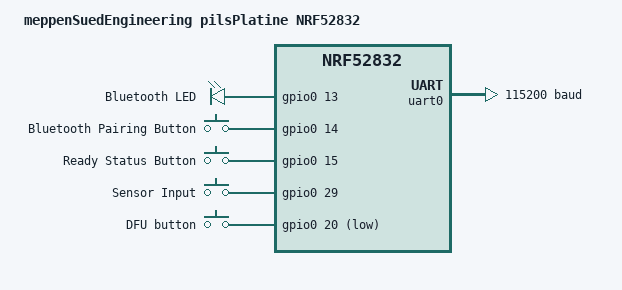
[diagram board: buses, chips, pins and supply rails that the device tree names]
/*
 * Copyright (c) 2017 Shawn Nock <shawn@monadnock.ca>
 * Copyright (c) 2017 Linaro Limited
 * Copyright (c) 2021 Michal Morsisko
 *
 * SPDX-License-Identifier: Apache-2.0
 */

/dts-v1/;
#include <nordic/nrf52832_qfaa.dtsi>
#include "pilsPlatine_nrf52832-pinctrl.dtsi"
#include <zephyr/dt-bindings/input/input-event-codes.h>

/ {
	model = "meppenSuedEngineering pilsPlatine NRF52832";
	compatible = "meppenSuedEngineering,pilsPlatine-nrf52832";

	chosen {
		zephyr,shell-uart = &uart0;
		zephyr,console = &uart0;
		zephyr,uart-mcumgr = &uart0;
		zephyr,bt-mon-uart = &uart0;
		zephyr,bt-c2h-uart = &uart0;
		zephyr,sram = &sram0;
		zephyr,flash = &flash0;
		zephyr,code-partition = &slot0_partition;
	};

	leds {
		compatible = "gpio-leds";
		led0: led_0 {
			gpios = <&gpio0 13 GPIO_ACTIVE_HIGH>;
			label = "Bluetooth LED";
		};
	};


	buttons {
		compatible = "gpio-keys";
		button0: button_0 {
			gpios = <&gpio0 14 (GPIO_PULL_UP | GPIO_ACTIVE_HIGH)>;
			label = "Bluetooth Pairing Button";
			zephyr,code = <INPUT_KEY_0>;
		};
		button1: button_1 {
			gpios = <&gpio0 15 (GPIO_PULL_UP | GPIO_ACTIVE_HIGH)>;
			label = "Ready Status Button";
			zephyr,code = <INPUT_KEY_1>;
		};
		button2: button_2 {
			gpios = <&gpio0 29 (GPIO_ACTIVE_HIGH)>;
			label = "Sensor Input";
			zephyr,code = <INPUT_KEY_2>;
		};
		button3: button_3 {
            label = "DFU button";
            gpios = <&gpio0 20 (GPIO_ACTIVE_LOW | GPIO_PULL_UP)>;
        };
	};

	/* These aliases are provided for compatibility with samples */
	aliases {
		led0 = &led0;
		sw0 = &button0;
		sw1 = &button1;
		mcuboot-button0 = &button0;
        mcuboot-led0 = &led0;
	};
};

&uicr {
	gpio-as-nreset;
};

&gpiote {
	status = "okay";
};

&gpio0 {
	status = "okay";
};

&uart0 {
	status = "okay";
	compatible = "nordic,nrf-uarte";
	current-speed = <115200>;
	pinctrl-0 = <&uart0_default>;
	pinctrl-1 = <&uart0_sleep>;
	pinctrl-names = "default", "sleep";
};

&flash0 {

	partitions {
		compatible = "fixed-partitions";
		#address-cells = <1>;
		#size-cells = <1>;

		boot_partition: partition@0 {
			label = "mcuboot";
			reg = <0x00000000 0xc000>;
		};
		slot0_partition: partition@c000 {
			label = "image-0";
			reg = <0x0000C000 0x32000>;
		};
		slot1_partition: partition@3e000 {
			label = "image-1";
			reg = <0x0003E000 0x32000>;
		};
		scratch_partition: partition@70000 {
			label = "image-scratch";
			reg = <0x00070000 0xa000>;
		};
		storage_partition: partition@7a000 {
			label = "storage";
			reg = <0x0007a000 0x00006000>;
		};
	};
};
